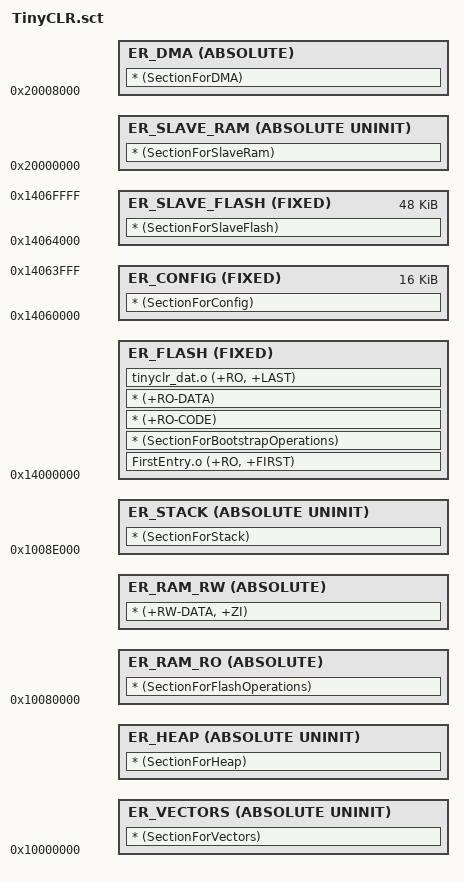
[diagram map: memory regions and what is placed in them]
LR_FLASH 0x14000000 ABSOLUTE 
{
    ER_FLASH 0x14000000 FIXED 
    {
        FirstEntry.o (+RO, +FIRST)
        * (SectionForBootstrapOperations)
        * (+RO-CODE)
        * (+RO-DATA)
        tinyclr_dat.o (+RO, +LAST)
    }
    ER_CONFIG 0x14060000 FIXED 0x00004000
    {
        * (SectionForConfig)
    }
    ER_SLAVE_FLASH 0x14064000 FIXED 0x0000C000
    {
        * (SectionForSlaveFlash)
    }
    ER_VECTORS 0x10000000 ABSOLUTE UNINIT
    {
        * (SectionForVectors)
    }
    ER_HEAP +0 ABSOLUTE UNINIT
    {
        * (SectionForHeap)
    }
    ER_RAM_RO 0x10080000 ABSOLUTE 
    {
        * (SectionForFlashOperations)
    }
    ER_RAM_RW +0 ABSOLUTE 
    {
        * (+RW-DATA, +ZI)
    }
    ER_STACK 0x1008E000 ABSOLUTE UNINIT
    {
        * (SectionForStack)
    }
    ER_SLAVE_RAM 0x20000000 ABSOLUTE UNINIT
    {
        * (SectionForSlaveRam)
    }
    ER_DMA 0x20008000 ABSOLUTE
    {
        * (SectionForDMA)
    }
}
